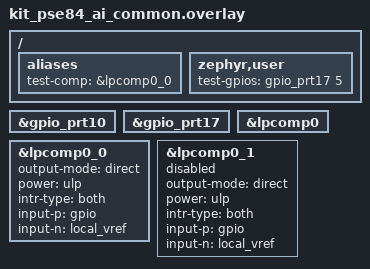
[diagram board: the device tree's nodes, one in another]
/*
 * Copyright (c) 2026 Infineon Technologies AG,
 * or an affiliate of Infineon Technologies AG.
 *
 * SPDX-License-Identifier: Apache-2.0
 */

/ {
	aliases {
		test-comp = &lpcomp0_0;
	};

	zephyr,user {
		/* P17.5 (test pin) connects to P10.4/BT_HOST_WAKE (input-p of the LPCOMP0_0) */
		test-gpios = <&gpio_prt17 5 0>;
	};
};

&gpio_prt10 {
	status = "okay";
};

&gpio_prt17 {
	status = "okay";
};

&lpcomp0 {
	status = "okay";
};

&lpcomp0_0 {
	status = "okay";
	output-mode = "direct";
	power = "ulp";
	intr-type = "both";
	input-p = "gpio";
	input-n = "local_vref";
};

&lpcomp0_1 {
	status = "disabled";
	output-mode = "direct";
	power = "ulp";
	intr-type = "both";
	input-p = "gpio";
	input-n = "local_vref";
};
